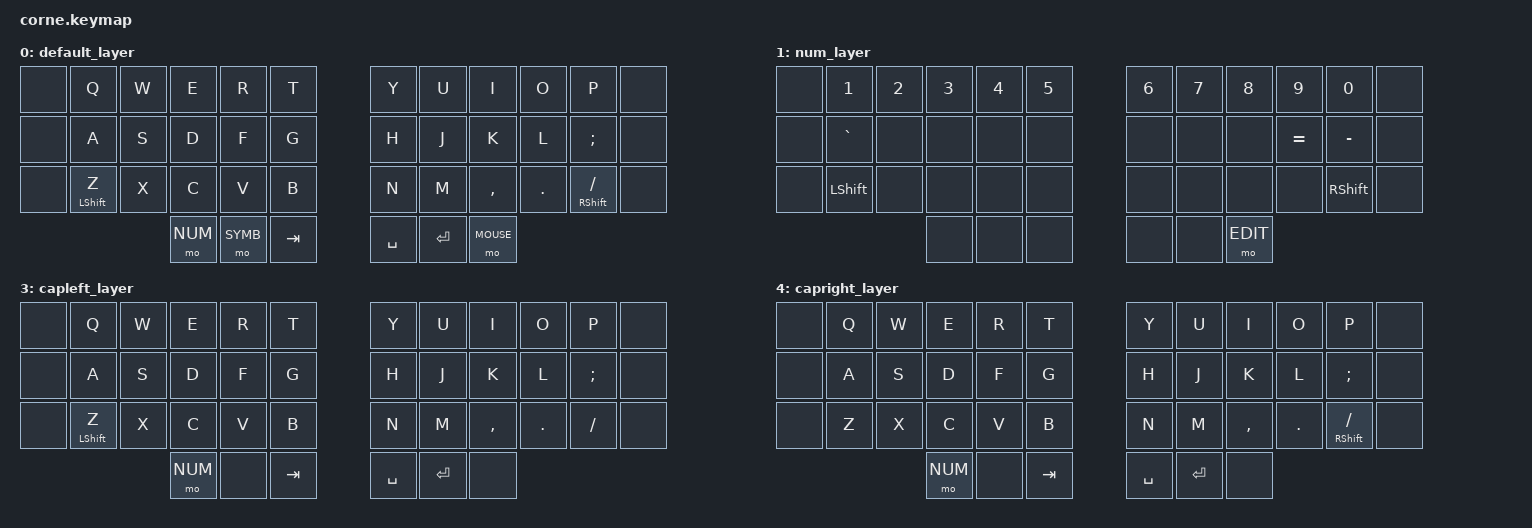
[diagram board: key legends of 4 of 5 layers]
/*
 * Copyright (c) 2020 The ZMK Contributors
 *
 * SPDX-License-Identifier: MIT
 */

#include <behaviors.dtsi>
#include <dt-bindings/zmk/keys.h>
#include <dt-bindings/zmk/bt.h>

#define DEFAULT 0
#define NUM 1
#define EDIT 2
#define CAPL 3
#define CAPR 4
#define SYMB 5
#define MOUSE 6

&mt {
    tapping-term-ms = <400>;
};


/ {
        keymap {
        compatible = "zmk,keymap";
      

        default_layer {
                        bindings = <
   &none &kp Q &kp W &kp E &kp R &kp T   &kp Y &kp U  &kp I     &kp O   &kp P    &none
   &none &kp A &kp S &kp D &kp F &kp G   &kp H &kp J  &kp K     &kp L   &kp SEMI &none
   &none &mt LSHIFT Z &kp X &kp C &kp V &kp B   &kp N &kp M  &kp COMMA &kp DOT &mt RSHIFT FSLH &none
                &mo NUM &mo SYMB &kp TAB   &kp SPACE &kp RET &mo MOUSE
                        >;
                };

        num_layer {
                        bindings = <
   &none  &kp N1   &kp N2   &kp N3  &kp N4  &kp N5 &kp N6 &kp N7  &kp N8   &kp N9   &kp N0  &none
   &none  &kp GRAVE    &none    &none   &none   &none  &none  &none   &none    &kp EQUAL    &kp MINUS   &none
   &none  &kp LSHIFT    &none    &none   &none   &none  &none  &none   &none    &none    &kp RSHIFT   &none
                    &none  &none   &none  &none  &none &mo EDIT
                        >;
                };
        
      edit_layer{
    bindings = <
        &none &kp ESC &none &none &none &none &none &none &none &kp PG_UP &kp PG_DN &kp HOME &kp BSPC &none
        &none &kp END &none &none &none &none &kp LEFT &kp DOWN &kp UP &kp RIGHT &none &none &none
        &none &none &none &none &none &none &none &none &none &none &none &none
               &none &none &none &none &none &none
                  >;
        };



    capleft_layer{
      bindings = <
        &none   &kp Q    &kp W    &kp E     &kp R    &kp T    &kp Y    &kp U     &kp I     &kp O    &kp P     &none
        &none   &kp A    &kp S    &kp D     &kp F    &kp G    &kp H    &kp J     &kp K     &kp L    &kp SEMI  &none
        &none   &mt LSHIFT Z &kp X    &kp C     &kp V    &kp B    &kp N    &kp M     &kp COMMA &kp DOT  &kp FSLH  &none
               &mo NUM    &none   &kp TAB   &kp SPACE &kp RET  &none
            >;

    };
    capright_layer{
      bindings = <
        &none   &kp Q    &kp W    &kp E     &kp R    &kp T    &kp Y    &kp U     &kp I     &kp O     &kp P     &none
        &none   &kp A    &kp S    &kp D     &kp F    &kp G    &kp H    &kp J     &kp K     &kp L     &kp SEMI  &none
        &none   &kp Z    &kp X    &kp C     &kp V    &kp B    &kp N    &kp M     &kp COMMA &kp DOT   &mt RSHIFT FSLH  &none
                       &mo NUM  &none   &kp TAB   &kp SPACE &kp RET  &none
      >;
    };

  };

    symbol_layer{
      bindings = <
        &none &kp EXCL        &kp AT    &kp HASH  &kp DLLR  &kp PRCNT &kp CARET &kp AMPS   &kp ASTRK  &kp LPAR   &kp RPAR          &none
        &none &kp TILDE       &kp UNDER &kp PLUS  &kp LCBR  &kp RCBR  &kp PIPE  &kp COLON  &kp DQT    &kp LT     &kp GT            &none
        &none &mt LSHIFT EXCL &none     &kp EQUAL &kp LBR   &kp RBR   &kp BSLH  &kp SEMI   &kp SQT    &kp COMMA  &kp QMARK           &none
                &none &none &trans &trans &trans &none
      >;
    };

    mouse_layer{
        bindings = <
          &none &none &none &none &none &none &none &none &none &none &none &none
          &none &none &none &none &none &none &none &none &none &none &none &none
          &none &none &none &none &none &none &none &none &none &none &none &none
                 &none &none &none &none &none &none
        >;
      };


};
